VERSION ""

NS_ :

BS_:

BU_:

BO_ 3221225472 VECTOR__INDEPENDENT_SIG_MSG: 0 Vector__XXX
 SG_ Range : 0|16@0+ (0.01,0) [0|127] "m" Vector__XXX
 SG_ Velocity : 0|16@0- (0.01,0) [-150|150] "Km/h" Vector__XXX
 SG_ Angle : 0|16@0- (0.01,0) [-15|15] "" Vector__XXX
 SG_ RCS : 0|16@0+ (1,0) [0|32767] "" Vector__XXX
 SG_ Range : 0|16@0+ (0.01,0) [0|127] "m" Vector__XXX
 SG_ Velocity : 0|16@0- (0.01,0) [-150|150] "Km/h" Vector__XXX
 SG_ Angle : 0|16@0- (0.01,0) [-15|15] "" Vector__XXX
 SG_ RCS : 0|16@0+ (1,0) [0|32767] "" Vector__XXX
 SG_ Range : 0|16@0+ (0.01,0) [0|127] "m" Vector__XXX
 SG_ Velocity : 0|16@0- (0.01,0) [-150|150] "Km/h" Vector__XXX
 SG_ Angle : 0|16@0- (0.01,0) [-15|15] "" Vector__XXX
 SG_ RCS : 0|16@0+ (1,0) [0|32767] "" Vector__XXX
 SG_ Range : 0|16@0+ (0.01,0) [0|127] "m" Vector__XXX
 SG_ Velocity : 0|16@0- (0.01,0) [-150|150] "Km/h" Vector__XXX
 SG_ Angle : 0|16@0- (0.01,0) [-15|15] "" Vector__XXX
 SG_ RCS : 0|16@0+ (1,0) [0|32767] "" Vector__XXX
 SG_ Range : 0|16@0+ (0.01,0) [0|127] "m" Vector__XXX
 SG_ Velocity : 0|16@0- (0.01,0) [-150|150] "Km/h" Vector__XXX
 SG_ Angle : 0|16@0- (0.01,0) [-15|15] "" Vector__XXX
 SG_ RCS : 0|16@0+ (1,0) [0|32767] "" Vector__XXX
 SG_ Range : 0|16@0+ (0.01,0) [0|127] "m" Vector__XXX
 SG_ Velocity : 0|16@0- (0.01,0) [-150|150] "Km/h" Vector__XXX
 SG_ Angle : 0|16@0- (0.01,0) [-15|15] "" Vector__XXX
 SG_ RCS : 0|16@0+ (1,0) [0|32767] "" Vector__XXX
 SG_ Range : 0|16@0+ (0.01,0) [0|127] "m" Vector__XXX
 SG_ Velocity : 0|16@0- (0.01,0) [-150|150] "Km/h" Vector__XXX
 SG_ Angle : 0|16@0- (0.01,0) [-15|15] "" Vector__XXX
 SG_ RCS : 0|16@0+ (1,0) [0|32767] "" Vector__XXX
 SG_ Range : 0|16@0+ (0.01,0) [0|127] "m" Vector__XXX
 SG_ Velocity : 0|16@0- (0.01,0) [-150|150] "Km/h" Vector__XXX
 SG_ Angle : 0|16@0- (0.01,0) [-15|15] "" Vector__XXX
 SG_ RCS : 0|16@0+ (1,0) [0|32767] "" Vector__XXX
 SG_ Range : 0|16@0+ (0.01,0) [0|127] "m" Vector__XXX
 SG_ Velocity : 0|16@0- (0.01,0) [-150|150] "Km/h" Vector__XXX
 SG_ Angle : 0|16@0- (0.01,0) [-15|15] "" Vector__XXX
 SG_ RCS : 0|16@0+ (1,0) [0|32767] "" Vector__XXX
 SG_ Range : 0|16@0+ (0.01,0) [0|127] "m" Vector__XXX
 SG_ Velocity : 0|16@0- (0.01,0) [-150|150] "Km/h" Vector__XXX
 SG_ Angle : 0|16@0- (0.01,0) [-15|15] "" Vector__XXX
 SG_ RCS : 0|16@0+ (1,0) [0|32767] "" Vector__XXX
 SG_ Range : 0|16@0+ (0.01,0) [0|127] "m" Vector__XXX
 SG_ Velocity : 0|16@0- (0.01,0) [-150|150] "Km/h" Vector__XXX
 SG_ Angle : 0|16@0- (0.01,0) [-15|15] "" Vector__XXX
 SG_ RCS : 0|16@0+ (1,0) [0|32767] "" Vector__XXX
 SG_ Range : 0|16@0+ (0.01,0) [0|127] "m" Vector__XXX
 SG_ Velocity : 0|16@0- (0.01,0) [-150|150] "Km/h" Vector__XXX
 SG_ Angle : 0|16@0- (0.01,0) [-15|15] "" Vector__XXX
 SG_ RCS : 0|16@0+ (1,0) [0|32767] "" Vector__XXX
 SG_ Range : 0|16@0+ (0.01,0) [0|127] "m" Vector__XXX
 SG_ Velocity : 0|16@0- (0.01,0) [-150|150] "Km/h" Vector__XXX
 SG_ Angle : 0|16@0- (0.01,0) [-15|15] "" Vector__XXX
 SG_ RCS : 0|16@0+ (1,0) [0|32767] "" Vector__XXX
 SG_ Range : 0|16@0+ (0.01,0) [0|127] "m" Vector__XXX
 SG_ Velocity : 0|16@0- (0.01,0) [-150|150] "Km/h" Vector__XXX
 SG_ Angle : 0|16@0- (0.01,0) [-15|15] "" Vector__XXX
 SG_ RCS : 0|16@0+ (1,0) [0|32767] "" Vector__XXX
 SG_ Range : 0|16@0+ (0.01,0) [0|127] "m" Vector__XXX
 SG_ Velocity : 0|16@0- (0.01,0) [-150|150] "Km/h" Vector__XXX
 SG_ Angle : 0|16@0- (0.01,0) [-15|15] "" Vector__XXX
 SG_ RCS : 0|16@0+ (1,0) [0|32767] "" Vector__XXX
 SG_ Range : 0|16@0+ (0.01,0) [0|127] "m" Vector__XXX
 SG_ Velocity : 0|16@0- (0.01,0) [-150|150] "Km/h" Vector__XXX
 SG_ Angle : 0|16@0- (0.01,0) [-15|15] "" Vector__XXX
 SG_ RCS : 0|16@0+ (1,0) [0|32767] "" Vector__XXX
 SG_ Range : 0|16@0+ (0.01,0) [0|127] "m" Vector__XXX
 SG_ Velocity : 0|16@0- (0.01,0) [-150|150] "Km/h" Vector__XXX
 SG_ Angle : 0|16@0- (0.01,0) [-15|15] "" Vector__XXX
 SG_ RCS : 0|16@0+ (1,0) [0|32767] "" Vector__XXX
 SG_ Range : 0|16@0+ (0.01,0) [0|127] "m" Vector__XXX
 SG_ Velocity : 0|16@0- (0.01,0) [-150|150] "Km/h" Vector__XXX
 SG_ Angle : 0|16@0- (0.01,0) [-15|15] "" Vector__XXX
 SG_ RCS : 0|16@0+ (1,0) [0|32767] "" Vector__XXX
 SG_ Range : 0|16@0+ (0.01,0) [0|127] "m" Vector__XXX
 SG_ Velocity : 0|16@0- (0.01,0) [-150|150] "Km/h" Vector__XXX
 SG_ Angle : 0|16@0- (0.01,0) [-15|15] "" Vector__XXX
 SG_ RCS : 0|16@0+ (1,0) [0|32767] "" Vector__XXX
 SG_ Range : 0|16@0+ (0.01,0) [0|127] "m" Vector__XXX
 SG_ Velocity : 0|16@0- (0.01,0) [-150|150] "Km/h" Vector__XXX
 SG_ Angle : 0|16@0- (0.01,0) [-15|15] "" Vector__XXX
 SG_ RCS : 0|16@0+ (1,0) [0|32767] "" Vector__XXX
 SG_ Range : 0|16@0+ (0.01,0) [0|127] "m" Vector__XXX
 SG_ Velocity : 0|16@0- (0.01,0) [-150|150] "Km/h" Vector__XXX
 SG_ Angle : 0|16@0- (0.01,0) [-15|15] "" Vector__XXX
 SG_ RCS : 0|16@0+ (1,0) [0|32767] "" Vector__XXX
 SG_ Range : 0|16@0+ (0.01,0) [0|127] "m" Vector__XXX
 SG_ Velocity : 0|16@0- (0.01,0) [-150|150] "Km/h" Vector__XXX
 SG_ Angle : 0|16@0- (0.01,0) [-15|15] "" Vector__XXX
 SG_ RCS : 0|16@0+ (1,0) [0|32767] "" Vector__XXX
 SG_ Range : 0|16@0+ (0.01,0) [0|127] "m" Vector__XXX
 SG_ Velocity : 0|16@0- (0.01,0) [-150|150] "Km/h" Vector__XXX
 SG_ Angle : 0|16@0- (0.01,0) [-15|15] "" Vector__XXX
 SG_ RCS : 0|16@0+ (1,0) [0|32767] "" Vector__XXX
 SG_ Range : 0|16@0+ (0.01,0) [0|127] "m" Vector__XXX
 SG_ Velocity : 0|16@0- (0.01,0) [-150|150] "Km/h" Vector__XXX
 SG_ Angle : 0|16@0- (0.01,0) [-15|15] "" Vector__XXX
 SG_ RCS : 0|16@0+ (1,0) [0|32767] "" Vector__XXX

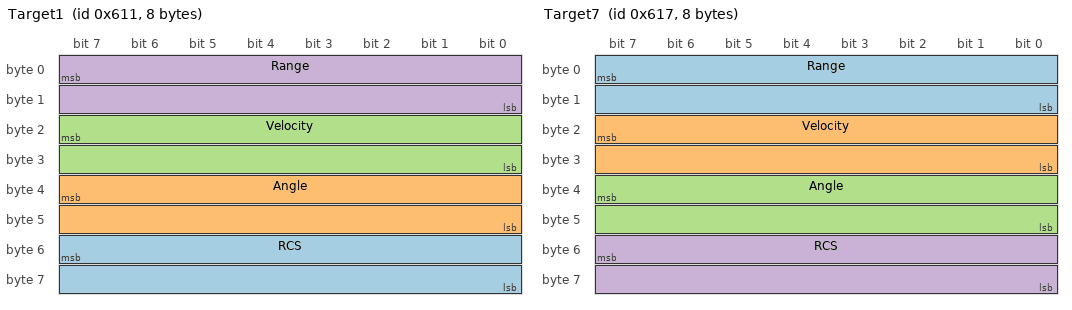
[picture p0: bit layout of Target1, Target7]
BO_ 1553 Target1: 8 Vector__XXX
 SG_ RCS : 55|16@0+ (1,0) [0|32767] "" Vector__XXX
 SG_ Angle : 39|16@0- (0.01,0) [-15|15] "" Vector__XXX
 SG_ Velocity : 23|16@0- (0.01,0) [-150|150] "Km/h" Vector__XXX
 SG_ Range : 7|16@0+ (0.01,0) [0|127] "m" Vector__XXX

BO_ 1559 Target7: 8 Vector__XXX
 SG_ Range : 7|16@0+ (0.01,0) [0|127] "m" Vector__XXX
 SG_ Velocity : 23|16@0- (0.01,0) [-150|150] "Km/h" Vector__XXX
 SG_ Angle : 39|16@0- (0.01,0) [-15|15] "" Vector__XXX
 SG_ RCS : 55|16@0+ (1,0) [0|32767] "" Vector__XXX

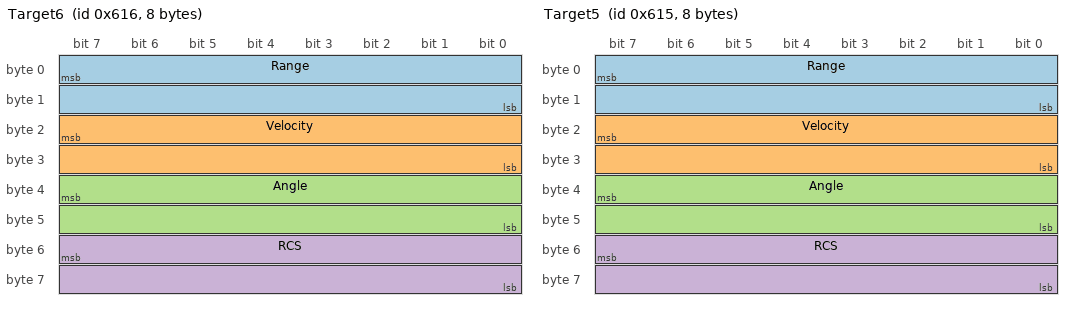
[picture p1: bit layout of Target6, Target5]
BO_ 1558 Target6: 8 Vector__XXX
 SG_ Range : 7|16@0+ (0.01,0) [0|127] "m" Vector__XXX
 SG_ Velocity : 23|16@0- (0.01,0) [-150|150] "Km/h" Vector__XXX
 SG_ Angle : 39|16@0- (0.01,0) [-15|15] "" Vector__XXX
 SG_ RCS : 55|16@0+ (1,0) [0|32767] "" Vector__XXX

BO_ 1557 Target5: 8 Vector__XXX
 SG_ Range : 7|16@0+ (0.01,0) [0|127] "m" Vector__XXX
 SG_ Velocity : 23|16@0- (0.01,0) [-150|150] "Km/h" Vector__XXX
 SG_ Angle : 39|16@0- (0.01,0) [-15|15] "" Vector__XXX
 SG_ RCS : 55|16@0+ (1,0) [0|32767] "" Vector__XXX

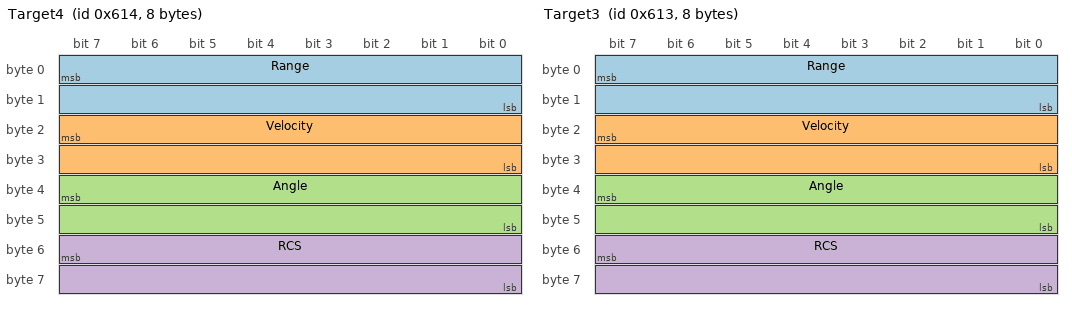
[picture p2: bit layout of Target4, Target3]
BO_ 1556 Target4: 8 Vector__XXX
 SG_ Range : 7|16@0+ (0.01,0) [0|127] "m" Vector__XXX
 SG_ Velocity : 23|16@0- (0.01,0) [-150|150] "Km/h" Vector__XXX
 SG_ Angle : 39|16@0- (0.01,0) [-15|15] "" Vector__XXX
 SG_ RCS : 55|16@0+ (1,0) [0|32767] "" Vector__XXX

BO_ 1555 Target3: 8 Vector__XXX
 SG_ Range : 7|16@0+ (0.01,0) [0|127] "m" Vector__XXX
 SG_ Velocity : 23|16@0- (0.01,0) [-150|150] "Km/h" Vector__XXX
 SG_ Angle : 39|16@0- (0.01,0) [-15|15] "" Vector__XXX
 SG_ RCS : 55|16@0+ (1,0) [0|32767] "" Vector__XXX

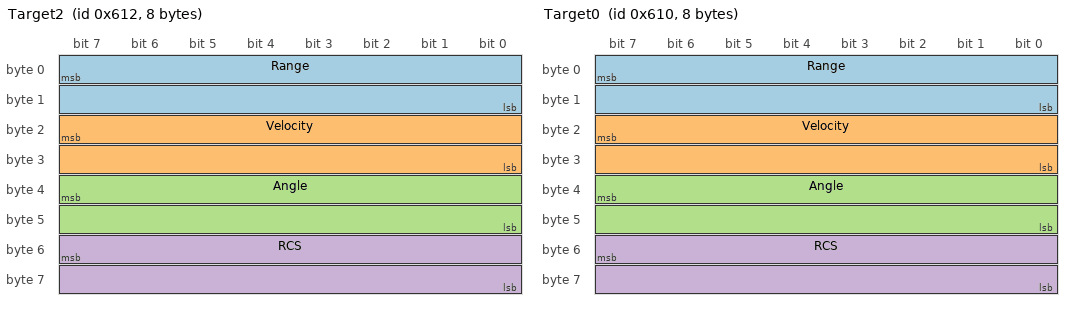
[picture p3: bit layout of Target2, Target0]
BO_ 1554 Target2: 8 Vector__XXX
 SG_ Range : 7|16@0+ (0.01,0) [0|127] "m" Vector__XXX
 SG_ Velocity : 23|16@0- (0.01,0) [-150|150] "Km/h" Vector__XXX
 SG_ Angle : 39|16@0- (0.01,0) [-15|15] "" Vector__XXX
 SG_ RCS : 55|16@0+ (1,0) [0|32767] "" Vector__XXX

BO_ 1552 Target0: 8 Vector__XXX
 SG_ Range : 7|16@0+ (0.01,0) [0|127] "m" Vector__XXX
 SG_ Velocity : 23|16@0- (0.01,0) [-150|150] "Km/h" Vector__XXX
 SG_ Angle : 39|16@0- (0.01,0) [-15|15] "" Vector__XXX
 SG_ RCS : 55|16@0+ (1,0) [0|32767] "" Vector__XXX

CM_ BO_ 3221225472 "This is a message for not used signals, created by Vector CANdb++ DBC OLE DB Provider.";
CM_ SG_ 3221225472 RCS "0x0: No Alarm
0x1: warning
0x2: Serious Warnning
0x3: Invalid";
CM_ SG_ 3221225472 RCS "0x0: No Alarm
0x1: warning
0x2: Serious Warnning
0x3: Invalid";
CM_ SG_ 3221225472 RCS "0x0: No Alarm
0x1: warning
0x2: Serious Warnning
0x3: Invalid";
CM_ SG_ 3221225472 RCS "0x0: No Alarm
0x1: warning
0x2: Serious Warnning
0x3: Invalid";
CM_ SG_ 3221225472 RCS "0x0: No Alarm
0x1: warning
0x2: Serious Warnning
0x3: Invalid";
CM_ SG_ 3221225472 RCS "0x0: No Alarm
0x1: warning
0x2: Serious Warnning
0x3: Invalid";
CM_ SG_ 3221225472 RCS "0x0: No Alarm
0x1: warning
0x2: Serious Warnning
0x3: Invalid";
CM_ SG_ 3221225472 RCS "0x0: No Alarm
0x1: warning
0x2: Serious Warnning
0x3: Invalid";
CM_ SG_ 3221225472 RCS "0x0: No Alarm
0x1: warning
0x2: Serious Warnning
0x3: Invalid";
CM_ SG_ 3221225472 RCS "0x0: No Alarm
0x1: warning
0x2: Serious Warnning
0x3: Invalid";
CM_ SG_ 3221225472 RCS "0x0: No Alarm
0x1: warning
0x2: Serious Warnning
0x3: Invalid";
CM_ SG_ 3221225472 RCS "0x0: No Alarm
0x1: warning
0x2: Serious Warnning
0x3: Invalid";
CM_ SG_ 3221225472 RCS "0x0: No Alarm
0x1: warning
0x2: Serious Warnning
0x3: Invalid";
CM_ SG_ 3221225472 RCS "0x0: No Alarm
0x1: warning
0x2: Serious Warnning
0x3: Invalid";
CM_ SG_ 3221225472 RCS "0x0: No Alarm
0x1: warning
0x2: Serious Warnning
0x3: Invalid";
CM_ SG_ 3221225472 RCS "0x0: No Alarm
0x1: warning
0x2: Serious Warnning
0x3: Invalid";
CM_ SG_ 3221225472 RCS "0x0: No Alarm
0x1: warning
0x2: Serious Warnning
0x3: Invalid";
CM_ SG_ 3221225472 RCS "0x0: No Alarm
0x1: warning
0x2: Serious Warnning
0x3: Invalid";
CM_ SG_ 3221225472 RCS "0x0: No Alarm
0x1: warning
0x2: Serious Warnning
0x3: Invalid";
CM_ SG_ 3221225472 RCS "0x0: No Alarm
0x1: warning
0x2: Serious Warnning
0x3: Invalid";
CM_ SG_ 3221225472 RCS "0x0: No Alarm
0x1: warning
0x2: Serious Warnning
0x3: Invalid";
CM_ SG_ 3221225472 RCS "0x0: No Alarm
0x1: warning
0x2: Serious Warnning
0x3: Invalid";
CM_ SG_ 3221225472 RCS "0x0: No Alarm
0x1: warning
0x2: Serious Warnning
0x3: Invalid";
CM_ SG_ 3221225472 RCS "0x0: No Alarm
0x1: warning
0x2: Serious Warnning
0x3: Invalid";
CM_ SG_ 1553 RCS "0x0: No Alarm
0x1: warning
0x2: Serious Warnning
0x3: Invalid";
CM_ SG_ 1559 RCS "0x0: No Alarm
0x1: warning
0x2: Serious Warnning
0x3: Invalid";
CM_ SG_ 1558 RCS "0x0: No Alarm
0x1: warning
0x2: Serious Warnning
0x3: Invalid";
CM_ SG_ 1557 RCS "0x0: No Alarm
0x1: warning
0x2: Serious Warnning
0x3: Invalid";
CM_ SG_ 1556 RCS "0x0: No Alarm
0x1: warning
0x2: Serious Warnning
0x3: Invalid";
CM_ SG_ 1555 RCS "0x0: No Alarm
0x1: warning
0x2: Serious Warnning
0x3: Invalid";
CM_ SG_ 1554 RCS "0x0: No Alarm
0x1: warning
0x2: Serious Warnning
0x3: Invalid";
CM_ SG_ 1552 RCS "0x0: No Alarm
0x1: warning
0x2: Serious Warnning
0x3: Invalid";
